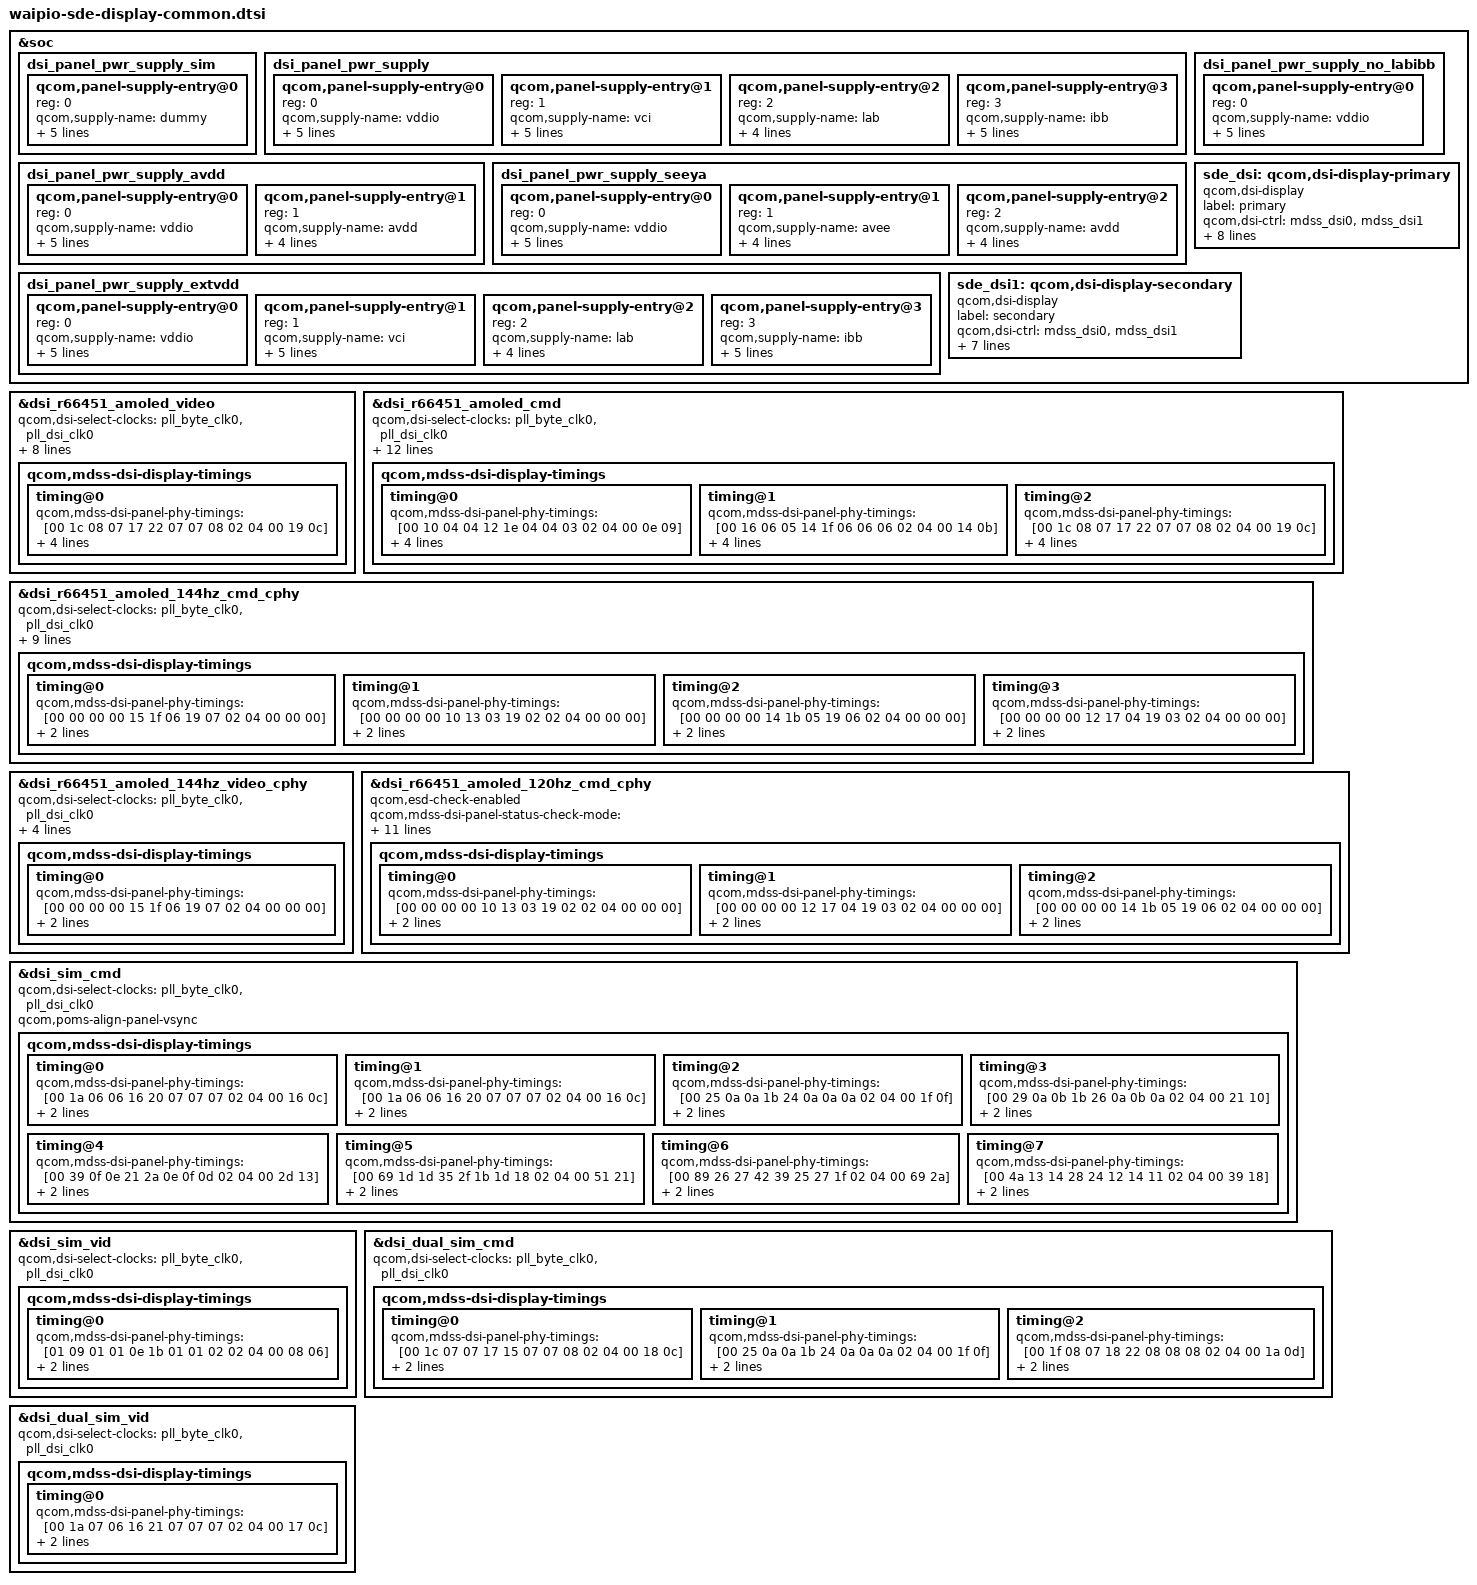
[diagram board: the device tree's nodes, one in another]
// SPDX-License-Identifier: BSD-3-Clause
/*
 * Copyright (c) Qualcomm Technologies, Inc. and/or its subsidiaries.
 */

#include "dsi-panel-sw43404-amoled-dsc-wqhd-cmd.dtsi"
#include "dsi-panel-sw43404-amoled-dsc-wqhd-video.dtsi"
#include "dsi-panel-sw43404-amoled-dsc-fhd-plus-cmd.dtsi"
#include "dsi-panel-sharp-dsc-4k-cmd.dtsi"
#include "dsi-panel-sharp-dsc-4k-video.dtsi"
#include "dsi-panel-sharp-dsc-qhd-plus-cmd.dtsi"
#include "dsi-panel-sharp-qsync-wqhd-cmd.dtsi"
#include "dsi-panel-sharp-qsync-wqhd-video.dtsi"
#include "dsi-panel-sharp-1080p-cmd.dtsi"
#include "dsi-panel-nt35597-truly-dualmipi-wqxga-cmd.dtsi"
#include "dsi-panel-nt35597-truly-dualmipi-wqxga-video.dtsi"
#include "dsi-panel-nt35695b-truly-fhd-cmd.dtsi"
#include "dsi-panel-nt35695b-truly-fhd-video.dtsi"
#include "dsi-panel-r66451-dsc-fhd-plus-144hz-cmd-cphy.dtsi"
#include "dsi-panel-r66451-dsc-fhd-plus-video.dtsi"
#include "dsi-panel-r66451-dsc-fhd-plus-cmd.dtsi"
#include "dsi-panel-r66451-dsc-fhd-plus-144hz-cmd.dtsi"
#include "dsi-panel-r66451-dsc-fhd-plus-144hz-video-cphy.dtsi"
#include "dsi-panel-r66451-dsc-fhd-plus-120hz-cmd-cphy.dtsi"
#include "dsi-panel-r66451-dsc-fhd-plus-sync-cmd.dtsi"
#include "dsi-panel-r66451-fhd-plus-90hz-cmd-cphy.dtsi"
#include "dsi-panel-r66451-fhd-plus-90hz-video-cphy.dtsi"
#include "dsi-panel-rm69299-visionox-fhd-plus-video.dtsi"
#include "dsi-panel-ext-bridge-1080p.dtsi"
#include "dsi-panel-sim-cmd.dtsi"
#include "dsi-panel-sim-video.dtsi"
#include "dsi-panel-sim-dsc375-cmd.dtsi"
#include "dsi-panel-sim-dsc-10bit-cmd.dtsi"
#include "dsi-panel-sim-dualmipi-cmd.dtsi"
#include "dsi-panel-sim-dualmipi-video.dtsi"
#include "dsi-panel-sim-dualmipi-dsc375-cmd.dtsi"
#include "dsi-panel-sim-sec-hd-cmd.dtsi"
#include "dsi-panel-sim-vdc-vid.dtsi"
#include "dsi-panel-nt36672e-fhd-plus-120-video.dtsi"
#include "dsi-panel-sim-vdc-cmd.dtsi"
#include "dsi-panel-nt35597-truly-dualmipi-wqxga-splitlink-cmd.dtsi"
#include "dsi-panel-nt35695b-truly-fhd-splitlink-cmd.dtsi"
#include "dsi-panel-nt36672c-fhd-plus-90hz-video-cphy.dtsi"
#include "dsi-panel-vtdr6130-dsc-fhd-plus-cmd.dtsi"
#include "dsi-panel-vtdr6130-dsc-fhd-plus-video.dtsi"
#include "dsi-panel-vtdr6130-qsync-dsc-fhd-plus-144hz-cmd.dtsi"
#include "dsi-panel-vtdr6130-qsync-dsc-fhd-plus-144hz-video.dtsi"
#include "dsi-panel-sy103-1280p-video.dtsi"
#include "dsi-panel-sy103-dualmipi-1280p-video.dtsi"
#include "dsi-panel-sy103-dsc-2544p-video.dtsi"
#include "dsi-panel-sy103-dualmipi-dsc-2544p-video.dtsi"

#include "waipio-sde-display-pinctrl.dtsi"

&soc {
	dsi_panel_pwr_supply_sim: dsi_panel_pwr_supply_sim {
		#address-cells = <1>;
		#size-cells = <0>;

		qcom,panel-supply-entry@0 {
			reg = <0>;
			qcom,supply-name = "dummy";
			qcom,supply-min-voltage = <1800000>;
			qcom,supply-max-voltage = <1800000>;
			qcom,supply-enable-load = <200000>;
			qcom,supply-disable-load = <80>;
			qcom,supply-post-on-sleep = <20>;
		};
	};

	dsi_panel_pwr_supply: dsi_panel_pwr_supply {
		#address-cells = <1>;
		#size-cells = <0>;

		qcom,panel-supply-entry@0 {
			reg = <0>;
			qcom,supply-name = "vddio";
			qcom,supply-min-voltage = <1800000>;
			qcom,supply-max-voltage = <1800000>;
			qcom,supply-enable-load = <200000>;
			qcom,supply-disable-load = <80>;
			qcom,supply-post-on-sleep = <20>;
		};

		qcom,panel-supply-entry@1 {
			reg = <1>;
			qcom,supply-name = "vci";
			qcom,supply-min-voltage = <3000000>;
			qcom,supply-max-voltage = <3000000>;
			qcom,supply-enable-load = <10000>;
			qcom,supply-disable-load = <0>;
			qcom,supply-post-on-sleep = <0>;
		};

		qcom,panel-supply-entry@2 {
			reg = <2>;
			qcom,supply-name = "lab";
			qcom,supply-min-voltage = <4600000>;
			qcom,supply-max-voltage = <6000000>;
			qcom,supply-enable-load = <0>;
			qcom,supply-disable-load = <0>;
		};

		qcom,panel-supply-entry@3 {
			reg = <3>;
			qcom,supply-name = "ibb";
			qcom,supply-min-voltage = <4600000>;
			qcom,supply-max-voltage = <6000000>;
			qcom,supply-enable-load = <0>;
			qcom,supply-disable-load = <0>;
			qcom,supply-post-on-sleep = <20>;
		};
	};

	dsi_panel_pwr_supply_avdd: dsi_panel_pwr_supply_avdd {
		#address-cells = <1>;
		#size-cells = <0>;

		qcom,panel-supply-entry@0 {
			reg = <0>;
			qcom,supply-name = "vddio";
			qcom,supply-min-voltage = <1800000>;
			qcom,supply-max-voltage = <1800000>;
			qcom,supply-enable-load = <200000>;
			qcom,supply-disable-load = <80>;
			qcom,supply-post-on-sleep = <20>;
		};

		qcom,panel-supply-entry@1 {
			reg = <1>;
			qcom,supply-name = "avdd";
			qcom,supply-min-voltage = <4600000>;
			qcom,supply-max-voltage = <6000000>;
			qcom,supply-enable-load = <100000>;
			qcom,supply-disable-load = <100>;
		};
	};

	dsi_panel_pwr_supply_seeya: dsi_panel_pwr_supply_seeya {
		#address-cells = <1>;
		#size-cells = <0>;

		qcom,panel-supply-entry@0 {
			reg = <0>;
			qcom,supply-name = "vddio";
			qcom,supply-min-voltage = <1800000>;
			qcom,supply-max-voltage = <1800000>;
			qcom,supply-enable-load = <200000>;
			qcom,supply-disable-load = <80>;
			qcom,supply-post-on-sleep = <10>;
		};

		qcom,panel-supply-entry@1 {
			reg = <1>;
			qcom,supply-name = "avee";
			qcom,supply-min-voltage = <4600000>;
			qcom,supply-max-voltage = <6000000>;
			qcom,supply-enable-load = <100000>;
			qcom,supply-disable-load = <10>;
		};

		 qcom,panel-supply-entry@2 {
			reg = <2>;
			qcom,supply-name = "avdd";
			qcom,supply-min-voltage = <4600000>;
			qcom,supply-max-voltage = <6000000>;
			qcom,supply-enable-load = <100000>;
			qcom,supply-disable-load = <10>;
                };
	};


	dsi_panel_pwr_supply_no_labibb: dsi_panel_pwr_supply_no_labibb {
		#address-cells = <1>;
		#size-cells = <0>;

		qcom,panel-supply-entry@0 {
			reg = <0>;
			qcom,supply-name = "vddio";
			qcom,supply-min-voltage = <1800000>;
			qcom,supply-max-voltage = <1800000>;
			qcom,supply-enable-load = <200000>;
			qcom,supply-disable-load = <80>;
			qcom,supply-post-on-sleep = <20>;
		};
	};

	dsi_panel_pwr_supply_extvdd: dsi_panel_pwr_supply_extvdd {
		#address-cells = <1>;
		#size-cells = <0>;

		qcom,panel-supply-entry@0 {
			reg = <0>;
			qcom,supply-name = "vddio";
			qcom,supply-min-voltage = <1800000>;
			qcom,supply-max-voltage = <1800000>;
			qcom,supply-enable-load = <200000>;
			qcom,supply-disable-load = <80>;
			qcom,supply-post-on-sleep = <20>;
		};

		qcom,panel-supply-entry@1 {
			reg = <1>;
			qcom,supply-name = "vci";
			qcom,supply-min-voltage = <3000000>;
			qcom,supply-max-voltage = <3000000>;
			qcom,supply-enable-load = <2000>;
			qcom,supply-disable-load = <0>;
			qcom,supply-post-on-sleep = <0>;
		};

		qcom,panel-supply-entry@2 {
			reg = <2>;
			qcom,supply-name = "lab";
			qcom,supply-min-voltage = <4600000>;
			qcom,supply-max-voltage = <6000000>;
			qcom,supply-enable-load = <0>;
			qcom,supply-disable-load = <0>;
		};

		qcom,panel-supply-entry@3 {
			reg = <3>;
			qcom,supply-name = "ibb";
			qcom,supply-min-voltage = <4600000>;
			qcom,supply-max-voltage = <6000000>;
			qcom,supply-enable-load = <0>;
			qcom,supply-disable-load = <0>;
			qcom,supply-post-on-sleep = <20>;
		};
	};

	sde_dsi: qcom,dsi-display-primary {
		compatible = "qcom,dsi-display";
		label = "primary";

		qcom,dsi-ctrl = <&mdss_dsi0 &mdss_dsi1>;
		qcom,dsi-phy = <&mdss_dsi_phy0 &mdss_dsi_phy1>;

		pinctrl-names = "panel_active", "panel_suspend";
		pinctrl-0 = <&sde_dsi_active &sde_te_active>;
		pinctrl-1 = <&sde_dsi_suspend &sde_te_suspend>;

		qcom,platform-te-gpio = <&tlmm 86 0>;
		qcom,panel-te-source = <0>;

		qcom,mdp = <&mdss_mdp>;
		qcom,dsi-default-panel = <&dsi_r66451_amoled_cmd>;
		qcom,demura-panel-id = <0x0122e700 0x000000b0>;
	};

	sde_dsi1: qcom,dsi-display-secondary {
		compatible = "qcom,dsi-display";
		label = "secondary";

		qcom,dsi-ctrl = <&mdss_dsi0 &mdss_dsi1>;
		qcom,dsi-phy = <&mdss_dsi_phy0 &mdss_dsi_phy1>;

		pinctrl-names = "panel_active", "panel_suspend";
		pinctrl-0 = <&sde_dsi1_active &sde_te1_active>;
		pinctrl-1 = <&sde_dsi1_suspend &sde_te1_suspend>;

		qcom,platform-te-gpio = <&tlmm 87 0>;
		qcom,panel-te-source = <1>;

		qcom,mdp = <&mdss_mdp>;
		qcom,demura-panel-id = <0x0 0x0>;
	};
};

/* PHY TIMINGS REVISION YK with reduced margins*/
&dsi_r66451_amoled_video {
	qcom,dsi-select-clocks = "pll_byte_clk0", "pll_dsi_clk0";
	qcom,dsi-supported-dfps-list = <120 90 60>;
	qcom,mdss-dsi-pan-enable-dynamic-fps;
	qcom,mdss-dsi-min-refresh-rate = <60>;
	qcom,mdss-dsi-max-refresh-rate = <120>;
	qcom,mdss-dsi-pan-fps-update = "dfps_immediate_porch_mode_vfp";

	qcom,dsi-dyn-clk-enable;
	qcom,dsi-dyn-clk-type = "constant-fps-adjust-hfp";

	qcom,mdss-dsi-display-timings {
		timing@0 {
			qcom,mdss-dsi-panel-phy-timings = [00 1c 08 07 17 22 07
				07 08 02 04 00 19 0c];
			qcom,display-topology = <2 2 1>;
			qcom,default-topology-index = <0>;

			qcom,dsi-dyn-clk-list = <846374400 842847840 844611120>;
		};
	};
};

&dsi_r66451_amoled_cmd {
	qcom,dsi-select-clocks = "pll_byte_clk0", "pll_dsi_clk0";
	qcom,dsi-select-sec-clocks = "pll_byte_clk1", "pll_dsi_clk1";

	qcom,dsi-dyn-clk-enable;

	qcom,mdss-dsi-panel-status-check-mode = "reg_read";
	qcom,mdss-dsi-panel-status-command = [06 01 00 01 00 00 01 0a];
	qcom,mdss-dsi-panel-status-command-state = "dsi_lp_mode";
	qcom,mdss-dsi-panel-status-value = <0x1c>;
	qcom,mdss-dsi-panel-status-read-length = <1>;
	qcom,esd-check-enabled;

	qcom,mdss-dsi-display-timings {
		timing@0 {
			qcom,mdss-dsi-panel-phy-timings = [00 10 04 04 12 1e 04
				04 03 02 04 00 0e 09];
			qcom,display-topology = <2 2 1>;
			qcom,default-topology-index = <0>;

			qcom,dsi-dyn-clk-list = <423187200 425303136 427429652>;
		};

		timing@1 {
			qcom,mdss-dsi-panel-phy-timings = [00 16 06 05 14 1f 06
				06 06 02 04 00 14 0b];
			qcom,display-topology = <2 2 1>;
			qcom,default-topology-index = <0>;

			qcom,dsi-dyn-clk-list = <634780800 637954704 641144480>;
		};

		timing@2 {
			qcom,mdss-dsi-panel-phy-timings = [00 1c 08 07 17 22 07
				07 08 02 04 00 19 0c];
			qcom,display-topology = <2 2 1>;
			qcom,default-topology-index = <0>;

			qcom,dsi-dyn-clk-list = <846374400 850606272 854859312>;
		};
	};
};


&dsi_r66451_amoled_144hz_cmd_cphy {
	qcom,dsi-select-clocks = "pll_byte_clk0", "pll_dsi_clk0";
	qcom,esd-check-enabled;
	qcom,mdss-dsi-panel-status-check-mode = "reg_read";
	qcom,mdss-dsi-panel-status-command = [06 01 00 01 00 00 01 0a];
	qcom,mdss-dsi-panel-status-command-state = "dsi_lp_mode";
	qcom,mdss-dsi-panel-status-value = <0x1c>;
	qcom,mdss-dsi-panel-status-read-length = <1>;

	qcom,mdss-dsi-display-timings {
		timing@0 {
			qcom,mdss-dsi-panel-phy-timings = [00 00 00 00 15 1f 06
					19 07 02 04 00 00 00];
			qcom,display-topology = <2 2 1>;
			qcom,default-topology-index = <0>;
		};
		timing@1 {
			qcom,mdss-dsi-panel-phy-timings = [00 00 00 00 10 13 03
					19 02 02 04 00 00 00];
			qcom,display-topology = <2 2 1>;
			qcom,default-topology-index = <0>;
		};

		timing@2 {
			qcom,mdss-dsi-panel-phy-timings = [00 00 00 00 14 1b 05
					19 06 02 04 00 00 00];
			qcom,display-topology = <2 2 1>;
			qcom,default-topology-index = <0>;
		};

		timing@3 {
			qcom,mdss-dsi-panel-phy-timings = [00 00 00 00 12 17 04
					19 03 02 04 00 00 00];
			qcom,display-topology = <2 2 1>;
			qcom,default-topology-index = <0>;
		};
	};
};


&dsi_r66451_amoled_144hz_video_cphy {
	qcom,dsi-select-clocks = "pll_byte_clk0", "pll_dsi_clk0";
	qcom,dsi-supported-dfps-list = <144 120 90 60>;
	qcom,mdss-dsi-pan-enable-dynamic-fps;
	qcom,mdss-dsi-pan-fps-update = "dfps_immediate_porch_mode_vfp";
	qcom,mdss-dsi-display-timings {
		timing@0 {
			qcom,mdss-dsi-panel-phy-timings = [00 00 00 00 15 1f 06
					19 07 02 04 00 00 00];
			qcom,display-topology = <2 2 1>;
			qcom,default-topology-index = <0>;
		};
	};
};

&dsi_r66451_amoled_120hz_cmd_cphy {
        qcom,esd-check-enabled;
        qcom,mdss-dsi-panel-status-check-mode = "reg_read";
        qcom,mdss-dsi-panel-status-command = [06 01 00 01 00 00 01 0a];
        qcom,mdss-dsi-panel-status-command-state = "dsi_lp_mode";
        qcom,mdss-dsi-panel-status-value = <0x1c>;
        qcom,mdss-dsi-panel-status-read-length = <1>;

        qcom,dsi-select-clocks = "pll_byte_clk0", "pll_dsi_clk0";
        qcom,dsi-select-sec-clocks = "pll_byte_clk1", "pll_dsi_clk1";
        qcom,mdss-dsi-display-timings {
                timing@0 {
                        qcom,mdss-dsi-panel-phy-timings = [00 00 00 00 10 13 03
                                        19 02 02 04 00 00 00];
                        qcom,display-topology = <2 2 1>;
                        qcom,default-topology-index = <0>;
                };

                timing@1 {
                        qcom,mdss-dsi-panel-phy-timings = [00 00 00 00 12 17 04
                                        19 03 02 04 00 00 00];
                        qcom,display-topology = <2 2 1>;
                        qcom,default-topology-index = <0>;
                };

                timing@2 {
                        qcom,mdss-dsi-panel-phy-timings = [00 00 00 00 14 1b 05
                                        19 06 02 04 00 00 00];
                        qcom,display-topology = <2 2 1>;
                        qcom,default-topology-index = <0>;
                };
        };
};

&dsi_sim_cmd {
        qcom,dsi-select-clocks = "pll_byte_clk0", "pll_dsi_clk0";
        qcom,poms-align-panel-vsync;
        qcom,mdss-dsi-display-timings {
                timing@0 { /* WQHD 60FPS cmd-vid mode*/
                        qcom,mdss-dsi-panel-phy-timings = [00 1a 06 06 16 20 07
                                07 07 02 04 00 16 0c];
                        qcom,display-topology = <1 1 1>,
                                                <2 2 1>;
                        qcom,default-topology-index = <1>;
                };

                timing@1 { /* WQHD 60FPS vid mode*/
                        qcom,mdss-dsi-panel-phy-timings = [00 1a 06 06 16 20 07
                                07 07 02 04 00 16 0c];
                        qcom,display-topology = <1 1 1>,
                                                <2 2 1>;
                        qcom,default-topology-index = <1>;
                };

                timing@2 { /* FHD+ 60FPS cmd mode*/
                        qcom,mdss-dsi-panel-phy-timings = [00 25 0a 0a 1b 24 0a
                                0a 0a 02 04 00 1f 0f];
                        qcom,display-topology = <1 1 1>,
                                                <2 2 1>;
                        qcom,default-topology-index = <1>;
                };

                timing@3 { /* HD 60FPS cmd mode */
                        qcom,mdss-dsi-panel-phy-timings = [00 29 0a 0b 1b 26 0a
                                0b 0a 02 04 00 21 10];
                        qcom,display-topology = <1 1 1>,
                                                <2 2 1>;
                        qcom,default-topology-index = <1>;
                };

                timing@4 { /* FHD+ 90FPS cmd mode*/
                        qcom,mdss-dsi-panel-phy-timings = [00 39 0f 0e 21 2a 0e
                                0f 0d 02 04 00 2d 13];
                        qcom,display-topology = <1 1 1>,
                                                <2 2 1>;
                        qcom,default-topology-index = <1>;
                };

                timing@5 { /* FHD+ 180 FPS cmd mode*/
                        qcom,mdss-dsi-panel-phy-timings = [00 69 1d 1d 35 2f 1b
                                1d 18 02 04 00 51 21];
                        qcom,display-topology = <2 2 1>;
                        qcom,default-topology-index = <0>;
                };

                timing@6 { /* FHD+ 240 FPS cmd mode*/
                        qcom,mdss-dsi-panel-phy-timings = [00 89 26 27 42 39 25
                                27 1f 02 04 00 69 2a];
                        qcom,display-topology = <2 2 1>;
                        qcom,default-topology-index = <0>;
                };

                timing@7 { /* FHD+ 120FPS cmd mode*/
                        qcom,mdss-dsi-panel-phy-timings = [00 4a 13 14 28 24 12
                                14 11 02 04 00 39 18];
                        qcom,display-topology = <1 1 1>,
                                                <2 2 1>;
                        qcom,default-topology-index = <1>;
                };

                /delete-node/ timing@8; /* FHD+ 144FPS cmd mode*/

                /delete-node/ timing@9; /* WQHD 1FPS cmd mode*/

                /delete-node/ timing@10; /* WQHD 5FPS cmd mode*/

                /delete-node/ timing@11; /* WQHD 10FPS cmd mode*/

                /delete-node/ timing@12; /* WQHD 24FPS cmd mode*/

                /delete-node/ timing@13; /* WQHD 30FPS cmd mode*/

                /delete-node/ timing@14; /* WQHD 60FPS cmd mode*/

                /delete-node/ timing@15; /* WQHD 90FPS cmd mode*/

                /delete-node/ timing@16; /* WQHD 120FPS cmd mode*/

                /delete-node/ timing@17; /* WQHD 144FPS cmd mode*/

                /delete-node/ timing@18; /* WQHD 180FPS cmd mode*/

                /delete-node/ timing@19; /* WQHD 165FPS cmd mode*/

                /delete-node/ timing@20; /* WQHD 180FPS cmd mode*/

	};
};

&dsi_sim_vid {
        qcom,dsi-select-clocks = "pll_byte_clk0", "pll_dsi_clk0";
        qcom,mdss-dsi-display-timings {
                timing@0 {
                        qcom,mdss-dsi-panel-phy-timings = [01 09 01 01 0e 1b 01
                                01 02 02 04 00 08 06];
                        qcom,display-topology = <1 0 1>,
                                                <2 0 1>;
                        qcom,default-topology-index = <0>;
                };
        };
};

&dsi_dual_sim_cmd {
	qcom,dsi-select-clocks = "pll_byte_clk0", "pll_dsi_clk0";
	qcom,mdss-dsi-display-timings {
		timing@0 { /* FHD 120FPS cmd mode*/
			qcom,mdss-dsi-panel-phy-timings = [00 1c 07 07 17 15 07
				07 08 02 04 00 18 0c];
			qcom,display-topology = <2 0 2>;
			qcom,default-topology-index = <0>;
		};

		timing@1 { /* 4K 40FPS cmd mode*/
			qcom,mdss-dsi-panel-phy-timings = [00 25 0a 0a 1b 24 0a
				0a 0a 02 04 00 1f 0f];
			qcom,display-topology = <2 0 2>;
			qcom,default-topology-index = <0>;
		};

		timing@2 { /* QHD+ 144FPS cmd mode*/
			qcom,mdss-dsi-panel-phy-timings = [00 1f 08 07 18 22 08
				08 08 02 04 00 1a 0d];
			qcom,display-topology = <2 2 2>;
			qcom,default-topology-index = <0>;
		};

		/delete-node/ timing@3;

		/delete-node/ timing@4;

		/delete-node/ timing@5;

		/delete-node/ timing@6;
	};
};

&dsi_dual_sim_vid {
	qcom,dsi-select-clocks = "pll_byte_clk0", "pll_dsi_clk0";
	qcom,mdss-dsi-display-timings {
		timing@0 {
			qcom,mdss-dsi-panel-phy-timings = [00 1a 07 06 16 21 07
				07 07 02 04 00 17 0c];
			qcom,display-topology = <2 0 2>,
						<1 0 2>;
			qcom,default-topology-index = <0>;
		};
	};
};
